VERSION ""

NS_ :

BS_:

BU_:

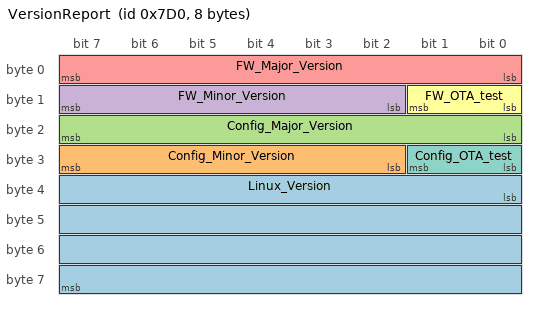
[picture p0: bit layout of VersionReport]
BO_ 2000 VersionReport: 8 Vector__XXX
 SG_ Linux_Version : 32|32@1+ (1,0) [0|4294967295] "" Vector__XXX
 SG_ Config_Minor_Version : 26|6@1+ (1,0) [0|63] "" Vector__XXX
 SG_ Config_Major_Version : 16|8@1+ (1,0) [0|255] "" Vector__XXX
 SG_ FW_Minor_Version : 10|6@1+ (1,0) [0|63] "" Vector__XXX
 SG_ FW_Major_Version : 0|8@1+ (1,0) [0|255] "" Vector__XXX
 SG_ FW_OTA_test : 8|2@1+ (1,0) [0|3] "" Vector__XXX
 SG_ Config_OTA_test : 24|2@1+ (1,0) [0|3] "" Vector__XXX
